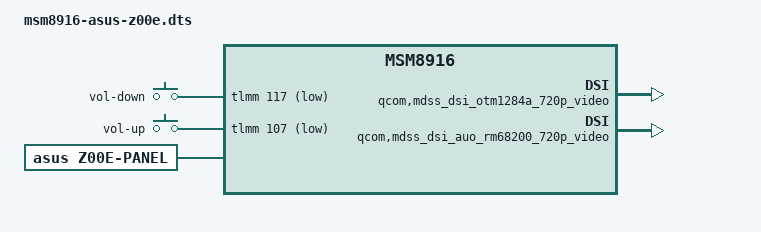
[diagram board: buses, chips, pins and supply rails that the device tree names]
// SPDX-License-Identifier: BSD-3-Clause

#include <skeleton64.dtsi>
#include <lk2nd.dtsi>

/ {
	/* SoC and board ids from the Lineage boot image for ZE500KL.
	 * 8916 production units use board-id 24 (ZE500KL PR); 21-23 are
	 * earlier builds. 8929/8939 ids are the other DTBs in that image.
	 */
	qcom,msm-id = <0xce 0x00 0xf8 0x00 0xf9 0x00 0xfa 0x00 239 0 241 0 263 0 268 0>;
	qcom,board-id = <20 0>, <21 0>, <22 0>, <23 0>, <24 0>,
			<30 0>, <31 0>, <32 0>, <33 0>,
			<22 1>, <23 1>, <24 1>, <40 1>;
};

&lk2nd {
	model = "Asus Zenfone 2 Laser ZE500KL";
	compatible = "asus,z00e";

	lk2nd,dtb-files = "msm8916-asus-z00e";

	gpio-keys {
		compatible = "gpio-keys";
		vol-down {
			lk2nd,code = <KEY_VOLUMEDOWN>;
			gpios = <&tlmm 117 (GPIO_ACTIVE_LOW | GPIO_PULL_UP)>;
		};
		vol-up {
			lk2nd,code = <KEY_VOLUMEUP>;
			gpios = <&tlmm 107 (GPIO_ACTIVE_LOW | GPIO_PULL_UP)>;
		};
	};

	panel {
		compatible = "asus,z00e-panel", "lk2nd,panel";

		qcom,mdss_dsi_otm1284a_720p_video {
			compatible = "asus,z00e-otm1284a";
		};
		qcom,mdss_dsi_auo_rm68200_720p_video {
			compatible = "asus,z00e-auo-rm68200";
		};
	};
};
